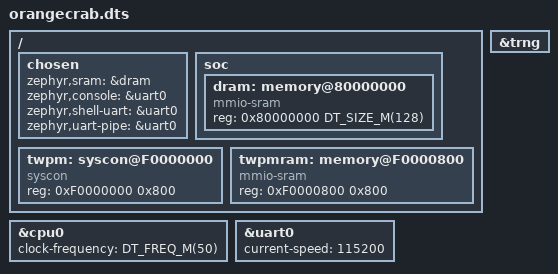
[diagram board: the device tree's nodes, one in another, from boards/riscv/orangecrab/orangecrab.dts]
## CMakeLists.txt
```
cmake_minimum_required(VERSION 3.20.0)

# Required so that Zephyr finds our custom boards. This does not disable lookup
# of boards from Zephyr repo.
set(BOARD_ROOT ${CMAKE_CURRENT_SOURCE_DIR})
find_package(Zephyr REQUIRED HINTS $ENV{ZEPHYR_BASE})

project(app LANGUAGES C VERSION 0.1.0)
zephyr_compile_options(-I${CMAKE_CURRENT_SOURCE_DIR}/../wolf)

target_sources(app PRIVATE
    src/main.c
    src/selftest.c
    src/debug.c
    src/tpm/plat/cancel.c
    src/tpm/plat/clock.c
    src/tpm/plat/entropy.c
    src/tpm/plat/locality.c
    src/tpm/plat/nv.c
    src/tpm/plat/physical_presence.c
    src/tpm/plat/power.c
    src/tpm/plat/run_command.c
    src/tpm/plat/unique.c
    src/tpm/init.c
    src/rng.c
)
target_include_directories(app PRIVATE include)
target_link_libraries(app PRIVATE ms-tpm-20-ref)
target_compile_definitions(app PRIVATE WOLFSSL_USER_SETTINGS)
```

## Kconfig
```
mainmenu "TwPM firmware configuration"

config TWPM_USE_UNSAFE_RNG
	bool "Usafe unsafe RNG"
	help
	  DANGER! Disables use of cryptographically-secure Random Number
	  Generator. This should be used only for testing purposes.

config TWPM_USE_HWINFO
	bool "Use hwinfo to generate TPM unique"
	default y
	depends on HWINFO

config TWPM_NV_EMULATE
	bool "Emulate NV using volatile memory"
	default n
	help
	  When enabled TPM has no persistent memory and all changes will be lost
	  after reset. Used mainly for testing and early platform bringup.

config TWPM_EMULATED_NV_SIZE
	int "Size of emulated NV in bytes"
	default 16384
	depends on TWPM_NV_EMULATE

config TWPM_RNG_TEST
	bool "Enable RNG (Random Number Generator) test"
	default false

source "Kconfig.zephyr"
```

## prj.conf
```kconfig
CONFIG_NEWLIB_LIBC=y
CONFIG_WOLFSSL=y
CONFIG_WOLFSSL_BUILTIN=y
CONFIG_WOLFSSL_SETTINGS_FILE="wolfssl-settings.h"
CONFIG_APP_LINK_WITH_WOLFSSL=y
CONFIG_TPM2_MS_REF=y
CONFIG_ENTROPY_GENERATOR=y
CONFIG_ENTROPY_DEVICE_RANDOM_GENERATOR=y
CONFIG_POSIX_API=y
CONFIG_POSIX_CLOCK=y
CONFIG_PTHREAD_IPC=y
# Increase stack size to avoid stack overflow
# TODO: TPM will run a separate thread because it can't block SPI/LPC, then this
# setting should be revisited
CONFIG_MAIN_STACK_SIZE=4096
CONFIG_HEAP_MEM_POOL_SIZE=32768
CONFIG_FLASH=y
CONFIG_FLASH_MAP=y

# Debugging
CONFIG_LOG=y
CONFIG_DEBUG_INFO=y
CONFIG_EXCEPTION_STACK_TRACE=y
CONFIG_DEBUG_THREAD_INFO=y
CONFIG_INIT_STACKS=y
CONFIG_THREAD_STACK_INFO=y
```

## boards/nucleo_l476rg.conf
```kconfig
CONFIG_GPIO=y
CONFIG_SPI=y
CONFIG_SPI_SLAVE=y
CONFIG_SPI_STM32_DMA=y
CONFIG_SPI_STM32_INTERRUPT=y
CONFIG_SPI_STM32_USE_HW_SS=y
CONFIG_SOC_FLASH_STM32=y
CONFIG_ENTROPY_STM32_RNG=y
CONFIG_HWINFO=y
```

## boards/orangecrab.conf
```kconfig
CONFIG_TWPM_NV_EMULATE=y
CONFIG_TWPM_CONST_UNIQUE=y
```

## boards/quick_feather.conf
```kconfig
# These options make TwPM implementation insecure! Should be removed after we
# gain support for hardware entropy source.
CONFIG_TEST_RANDOM_GENERATOR=y
CONFIG_TIMER_RANDOM_GENERATOR=y
CONFIG_TWPM_USE_UNSAFE_RNG=y
```

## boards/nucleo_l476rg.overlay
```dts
&flash {
	status = "okay";

	partitions {
		compatible = "fixed-partitions";
		#address-cells = <1>;
		#size-cells = <1>;

		nv_integrity: partition@70800 {
			label = "nv_integrity";
			reg = <0x70800 0x800>;
		};

		// NV size must match with NV_MEMORY_SIZE macro in ms-tpm's
		// Implementation.h
		nv_storage: partition@71800 {
			label = "nv_storage";
			reg = <0x71800 0x4000>;
		};
	};
};

&dma1 {
	status = "okay";
};

&spi1 {
	status = "disabled";
};

&spi2 {
	/*
	 * See https://docs.zephyrproject.org/3.0.0/reference/devicetree/bindings/dma/st%2Cstm32-dma-v2.html
	 */
	dmas = <&dma1 5 1 0x20440>,
	       <&dma1 4 1 0x20480>;
	dma-names = "tx", "rx";
};

&spi3 {
	status = "disabled";
};
```

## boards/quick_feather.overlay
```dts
/ {
	aliases {
		lpcfpga = &twpm_lpc_fpga;
	};

	twpm_lpc_fpga: twpm_lpc_fpga@40020000 {
		compatible = "twpm,lpc_fpga";
		reg = <0x40020000 0x400>;
		interrupt-parent = <&nvic>;
		interrupts = <4 1>;
	};
};

&spiflash {
	partitions {
		compatible = "fixed-partitions";
		#address-cells = <1>;
		#size-cells = <1>;

		/* Put directly after the application region.
		 * Based on memory map from
		 * https://github.com/QuickLogic-Corp/qorc-sdk/blob/d61d064146c0ee927aa12b088b3bbbce60615f4d/docs/source/qorc-setup/qorc-flash-memory-map-addresses.svg
		 */

		nv_integrity: partition@ee000 {
			label = "nv_integrity";
			reg = <0xee000 0x1000>;
		};

		// NV size must match with NV_MEMORY_SIZE macro in ms-tpm's
		// Implementation.h
		nv_storage: partition@ef000 {
			label = "nv_storage";
			reg = <0xef000 0x4000>;
		};
	};
};
```

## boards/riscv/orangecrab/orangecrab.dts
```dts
/dts-v1/;

#include <neorv32.dtsi>
#include <freq.h>
#include <mem.h>

/ {
	chosen {
		zephyr,sram = &dram;
		zephyr,console = &uart0;
		zephyr,shell-uart = &uart0;
		zephyr,uart-pipe = &uart0;
	};

	soc {
		dram: memory@80000000 {
			compatible = "mmio-sram";
			reg = <0x80000000 DT_SIZE_M(128)>;
		};
	};

	twpm: syscon@F0000000 {
		compatible = "syscon";
		status = "okay";
		reg = <0xF0000000 0x800>;
	};

	twpmram: memory@F0000800 {
		compatible = "mmio-sram";
		reg = < 0xF0000800 0x800 >;
	};
};

&cpu0 {
	clock-frequency = <DT_FREQ_M(50)>;
};

&uart0 {
	current-speed = <115200>;
	status = "okay";
};

&trng {
	status = "okay";
};
```

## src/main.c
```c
/*
 * Copyright (c) 2022 3mdeb
 *
 * SPDX-License-Identifier: Apache-2.0
 */

#include <zephyr/kernel.h>
#include <zephyr/drivers/gpio.h>
#include <zephyr/drivers/spi.h>
#include <zephyr/drivers/syscon.h>
#include <zephyr/logging/log.h>

#include <twpm/tpm.h>
#include <twpm/test.h>
#include <twpm/platform.h>

#include <string.h>
#include <limits.h>

#include <assert.h>

LOG_MODULE_REGISTER(main);

K_THREAD_STACK_DEFINE(tpm_thread_stack, 16384);
struct k_thread tpm_thread;
k_tid_t tpm_thread_id;
K_SEM_DEFINE(tpm_cmd_sem, 0, 1);

#ifdef CONFIG_TWPM_RNG_TEST
K_THREAD_STACK_DEFINE(rng_thread_stack, 512);
struct k_thread rng_thread;
#endif

static uint8_t tpm_cmd[2048];
static uint32_t tpm_cmd_size = 0;

extern unsigned char _g_locality;

#define TWPM_RAM_BASE       ((void *)DT_REG_ADDR(DT_NODELABEL(twpmram)))

static void tpm_thread_entry(void *p0, void *p1, void *p2) {
	while(1) {
		if (k_sem_take(&tpm_cmd_sem, K_MSEC(1000)) == 0) {
			uint8_t tpm_rsp_buf[2048];
			uint8_t *tpm_response = tpm_rsp_buf;
			uint32_t tpm_response_size = sizeof tpm_rsp_buf;
			const struct device *const dev = DEVICE_DT_GET(DT_NODELABEL(twpm));

			LOG_HEXDUMP_DBG(tpm_cmd, tpm_cmd_size, "TPM command:");
			LOG_INF("Executing %s", tpmdbg_decode_cc(&tpm_cmd[6]));
			twpm_run_command(tpm_cmd_size, tpm_cmd, &tpm_response_size, &tpm_response);

			if (tpm_response_size > 2048) {
				LOG_ERR("Illegal response size %x", tpm_response_size);
				k_oops();
			}

			LOG_HEXDUMP_DBG(tpm_response, tpm_response_size, "TPM response:");
			LOG_INF("TPM command result: %s", tpmdbg_decode_rc(&tpm_response[6]));

			memcpy(TWPM_RAM_BASE, tpm_response, tpm_response_size);
			syscon_write_reg(dev, TWPM_REG_COMPLETE, 1);

			irq_enable(TWPM_IRQ);
		} else {
			// Update internal state of 64-bit emulated clock (STM32
			// provides only 32-bit clock). We need to do this
			// periodically to detect clock overflows.
			_plat__TimerRead();
		}
	}
}

static void twpm_isr(const struct device *const dev)
{
	uint32_t op_type = 0;
	uint32_t locality = 0;

	irq_disable(TWPM_IRQ);

	syscon_read_reg(dev, TWPM_REG_OP_TYPE, &op_type);
	syscon_read_reg(dev, TWPM_REG_BUF_SIZE, &tpm_cmd_size);
	syscon_read_reg(dev, TWPM_REG_LOCALITY, &locality);

	LOG_INF("IRQ: op_type = %x, cmd_size = %x, locality = %x",
	        op_type, tpm_cmd_size, locality);

	if (op_type == TWPM_REG_OP_TYPE_CMD) {
		if (tpm_cmd_size > 2048) {
			LOG_ERR("Illegal command size %x", tpm_cmd_size);
			k_oops();
		}
		if (locality > 4) {
			LOG_ERR("Illegal locality %x", locality);
			k_oops();
		}
		_g_locality = locality & 0x0F;

		memcpy(tpm_cmd, TWPM_RAM_BASE, tpm_cmd_size);
		k_sem_give(&tpm_cmd_sem);
	} else {
		LOG_ERR("Unknown operation requested, giving up");
		k_oops();
	}
}

#ifdef CONFIG_TWPM_RNG_TEST
extern void twpm_test_rng();
#endif

int main(void)
{
	LOG_INF("Starting TwPM");

	IRQ_CONNECT(TWPM_IRQ, 0, twpm_isr, DEVICE_DT_GET(DT_NODELABEL(twpm)), 0);
	irq_enable(TWPM_IRQ);

	twpm_init();
	//twpm_selftest();

	tpm_thread_id = k_thread_create(&tpm_thread, tpm_thread_stack,
					K_THREAD_STACK_SIZEOF(tpm_thread_stack),
					tpm_thread_entry, NULL, NULL, NULL, 5, 0,
					K_NO_WAIT);

#ifdef CONFIG_TWPM_RNG_TEST
	k_thread_create(&rng_thread, rng_thread_stack,
			K_THREAD_STACK_SIZEOF(rng_thread_stack), twpm_test_rng,
			NULL, NULL, NULL, 5, 0, K_NO_WAIT);
#endif

	return 0;
}
```

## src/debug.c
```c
// Based on ms-tpm-20-ref/Samples/Nucleo-TPM/Shared/TPMDevice/src/TpmDevice.c

#include <twpm/test.h>
#include <stdio.h>

#include <Implementation.h>
#include <GpMacros.h>
#include <Capabilities.h>
#include <Memory_fp.h>
#include <TpmTypes.h>

#define TPM_RC_MAX_FM1 (TPM_RC)(RC_FMT1 + 0x03F)

typedef struct
{
    uint32_t index;
    char* str;
} lookup_t;

const lookup_t tpm_cc_table[] =
{
#if CC_NV_UndefineSpaceSpecial == YES
    {TPM_CC_NV_UndefineSpaceSpecial, "TPM_CC_NV_UndefineSpaceSpecial"},
#endif
#if CC_EvictControl == YES
    {TPM_CC_EvictControl, "TPM_CC_EvictControl"},
#endif
#if CC_HierarchyControl == YES
    {TPM_CC_HierarchyControl, "TPM_CC_HierarchyControl"},
#endif
#if CC_NV_UndefineSpace == YES
    {TPM_CC_NV_UndefineSpace, "TPM_CC_NV_UndefineSpace"},
#endif
#if CC_ChangeEPS == YES
    {TPM_CC_ChangeEPS, "TPM_CC_ChangeEPS"},
#endif
#if CC_ChangePPS == YES
    {TPM_CC_ChangePPS, "TPM_CC_ChangePPS"},
#endif
#if CC_Clear == YES
    {TPM_CC_Clear, "TPM_CC_Clear"},
#endif
#if CC_ClearControl == YES
    {TPM_CC_ClearControl, "TPM_CC_ClearControl"},
#endif
#if CC_ClockSet == YES
    {TPM_CC_ClockSet, "TPM_CC_ClockSet"},
#endif
#if CC_HierarchyChangeAuth == YES
    {TPM_CC_HierarchyChangeAuth, "TPM_CC_HierarchyChangeAuth"},
#endif
#if CC_NV_DefineSpace == YES
    {TPM_CC_NV_DefineSpace, "TPM_CC_NV_DefineSpace"},
#endif
#if CC_PCR_Allocate == YES
    {TPM_CC_PCR_Allocate, "TPM_CC_PCR_Allocate"},
#endif
#if CC_PCR_SetAuthPolicy == YES
    {TPM_CC_PCR_SetAuthPolicy, "TPM_CC_PCR_SetAuthPolicy"},
#endif
#if CC_PP_Commands == YES
    {TPM_CC_PP_Commands, "TPM_CC_PP_Commands"},
#endif
#if CC_SetPrimaryPolicy == YES
    {TPM_CC_SetPrimaryPolicy, "TPM_CC_SetPrimaryPolicy"},
#endif
#if CC_FieldUpgradeStart == YES
    {TPM_CC_FieldUpgradeStart, "TPM_CC_FieldUpgradeStart"},
#endif
#if CC_ClockRateAdjust == YES
    {TPM_CC_ClockRateAdjust, "TPM_CC_ClockRateAdjust"},
#endif
#if CC_CreatePrimary == YES
    {TPM_CC_CreatePrimary, "TPM_CC_CreatePrimary"},
#endif
#if CC_NV_GlobalWriteLock == YES
    {TPM_CC_NV_GlobalWriteLock, "TPM_CC_NV_GlobalWriteLock"},
#endif
#if CC_GetCommandAuditDigest == YES
    {TPM_CC_GetCommandAuditDigest, "TPM_CC_GetCommandAuditDigest"},
#endif
#if CC_NV_Increment == YES
    {TPM_CC_NV_Increment, "TPM_CC_NV_Increment"},
#endif
#if CC_NV_SetBits == YES
    {TPM_CC_NV_SetBits, "TPM_CC_NV_SetBits"},
#endif
#if CC_NV_Extend == YES
    {TPM_CC_NV_Extend, "TPM_CC_NV_Extend"},
#endif
#if CC_NV_Write == YES
    {TPM_CC_NV_Write, "TPM_CC_NV_Write"},
#endif
#if CC_NV_WriteLock == YES
    {TPM_CC_NV_WriteLock, "TPM_CC_NV_WriteLock"},
#endif
#if CC_DictionaryAttackLockReset == YES
    {TPM_CC_DictionaryAttackLockReset, "TPM_CC_DictionaryAttackLockReset"},
#endif
#if CC_DictionaryAttackParameters == YES
    {TPM_CC_DictionaryAttackParameters, "TPM_CC_DictionaryAttackParameters"},
#endif
#if CC_NV_ChangeAuth == YES
    {TPM_CC_NV_ChangeAuth, "TPM_CC_NV_ChangeAuth"},
#endif
#if CC_PCR_Event == YES
    {TPM_CC_PCR_Event, "TPM_CC_PCR_Event"},
#endif
#if CC_PCR_Reset == YES
    {TPM_CC_PCR_Reset, "TPM_CC_PCR_Reset"},
#endif
#if CC_SequenceComplete == YES
    {TPM_CC_SequenceComplete, "TPM_CC_SequenceComplete"},
#endif
#if CC_SetAlgorithmSet == YES
    {TPM_CC_SetAlgorithmSet, "TPM_CC_SetAlgorithmSet"},
#endif
#if CC_SetCommandCodeAuditStatus == YES
    {TPM_CC_SetCommandCodeAuditStatus, "TPM_CC_SetCommandCodeAuditStatus"},
#endif
#if CC_FieldUpgradeData == YES
    {TPM_CC_FieldUpgradeData, "TPM_CC_FieldUpgradeData"},
#endif
#if CC_IncrementalSelfTest == YES
    {TPM_CC_IncrementalSelfTest, "TPM_CC_IncrementalSelfTest"},
#endif
#if CC_SelfTest == YES
    {TPM_CC_SelfTest, "TPM_CC_SelfTest"},
#endif
#if CC_Startup == YES
    {TPM_CC_Startup, "TPM_CC_Startup"},
#endif
#if CC_Shutdown == YES
    {TPM_CC_Shutdown, "TPM_CC_Shutdown"},
#endif
#if CC_StirRandom == YES
    {TPM_CC_StirRandom, "TPM_CC_StirRandom"},
#endif
#if CC_ActivateCredential == YES
    {TPM_CC_ActivateCredential, "TPM_CC_ActivateCredential"},
#endif
#if CC_Certify == YES
    {TPM_CC_Certify, "TPM_CC_Certify"},
#endif
#if CC_PolicyNV == YES
    {TPM_CC_PolicyNV, "TPM_CC_PolicyNV"},
#endif
#if CC_CertifyCreation == YES
    {TPM_CC_CertifyCreation, "TPM_CC_CertifyCreation"},
#endif
#if CC_Duplicate == YES
    {TPM_CC_Duplicate, "TPM_CC_Duplicate"},
#endif
#if CC_GetTime == YES
    {TPM_CC_GetTime, "TPM_CC_GetTime"},
#endif
#if CC_GetSessionAuditDigest == YES
    {TPM_CC_GetSessionAuditDigest, "TPM_CC_GetSessionAuditDigest"},
#endif
#if CC_NV_Read == YES
    {TPM_CC_NV_Read, "TPM_CC_NV_Read"},
#endif
#if CC_NV_ReadLock == YES
    {TPM_CC_NV_ReadLock, "TPM_CC_NV_ReadLock"},
#endif
#if CC_ObjectChangeAuth == YES
    {TPM_CC_ObjectChangeAuth, "TPM_CC_ObjectChangeAuth"},
#endif
#if CC_PolicySecret == YES
    {TPM_CC_PolicySecret, "TPM_CC_PolicySecret"},
#endif
#if CC_Rewrap == YES
    {TPM_CC_Rewrap, "TPM_CC_Rewrap"},
#endif
#if CC_Create == YES
    {TPM_CC_Create, "TPM_CC_Create"},
#endif
#if CC_ECDH_ZGen == YES
    {TPM_CC_ECDH_ZGen, "TPM_CC_ECDH_ZGen"},
#endif
#if CC_HMAC == YES
    {TPM_CC_HMAC, "TPM_CC_HMAC"},
#endif
#if CC_MAC == YES
    {TPM_CC_MAC, "TPM_CC_MAC"},
#endif
#if CC_Import == YES
    {TPM_CC_Import, "TPM_CC_Import"},
#endif
#if CC_Load == YES
    {TPM_CC_Load, "TPM_CC_Load"},
#endif
#if CC_Quote == YES
    {TPM_CC_Quote, "TPM_CC_Quote"},
#endif
#if CC_RSA_Decrypt == YES
    {TPM_CC_RSA_Decrypt, "TPM_CC_RSA_Decrypt"},
#endif
#if CC_HMAC_Start == YES
    {TPM_CC_HMAC_Start, "TPM_CC_HMAC_Start"},
#endif
#if CC_MAC_Start == YES
    {TPM_CC_MAC_Start, "TPM_CC_MAC_Start"},
#endif
#if CC_SequenceUpdate == YES
    {TPM_CC_SequenceUpdate, "TPM_CC_SequenceUpdate"},
#endif
#if CC_Sign == YES
    {TPM_CC_Sign, "TPM_CC_Sign"},
#endif
#if CC_Unseal == YES
    {TPM_CC_Unseal, "TPM_CC_Unseal"},
#endif
#if CC_PolicySigned == YES
    {TPM_CC_PolicySigned, "TPM_CC_PolicySigned"},
#endif
#if CC_ContextLoad == YES
    {TPM_CC_ContextLoad, "TPM_CC_ContextLoad"},
#endif
#if CC_ContextSave == YES
    {TPM_CC_ContextSave, "TPM_CC_ContextSave"},
#endif
#if CC_ECDH_KeyGen == YES
    {TPM_CC_ECDH_KeyGen, "TPM_CC_ECDH_KeyGen"},
#endif
#if CC_EncryptDecrypt == YES
    {TPM_CC_EncryptDecrypt, "TPM_CC_EncryptDecrypt"},
#endif
#if CC_FlushContext == YES
    {TPM_CC_FlushContext, "TPM_CC_FlushContext"},
#endif
#if CC_LoadExternal == YES
    {TPM_CC_LoadExternal, "TPM_CC_LoadExternal"},
#endif
#if CC_MakeCredential == YES
    {TPM_CC_MakeCredential, "TPM_CC_MakeCredential"},
#endif
#if CC_NV_ReadPublic == YES
    {TPM_CC_NV_ReadPublic, "TPM_CC_NV_ReadPublic"},
#endif
#if CC_PolicyAuthorize == YES
    {TPM_CC_PolicyAuthorize, "TPM_CC_PolicyAuthorize"},
#endif
#if CC_PolicyAuthValue == YES
    {TPM_CC_PolicyAuthValue, "TPM_CC_PolicyAuthValue"},
#endif
#if CC_PolicyCommandCode == YES
    {TPM_CC_PolicyCommandCode, "TPM_CC_PolicyCommandCode"},
#endif
#if CC_PolicyCounterTimer == YES
    {TPM_CC_PolicyCounterTimer, "TPM_CC_PolicyCounterTimer"},
#endif
#if CC_PolicyCpHash == YES
    {TPM_CC_PolicyCpHash, "TPM_CC_PolicyCpHash"},
#endif
#if CC_PolicyLocality == YES
    {TPM_CC_PolicyLocality, "TPM_CC_PolicyLocality"},
#endif
#if CC_PolicyNameHash == YES
    {TPM_CC_PolicyNameHash, "TPM_CC_PolicyNameHash"},
#endif
#if CC_PolicyOR == YES
    {TPM_CC_PolicyOR, "TPM_CC_PolicyOR"},
#endif
#if CC_PolicyTicket == YES
    {TPM_CC_PolicyTicket, "TPM_CC_PolicyTicket"},
#endif
#if CC_ReadPublic == YES
    {TPM_CC_ReadPublic, "TPM_CC_ReadPublic"},
#endif
#if CC_RSA_Encrypt == YES
    {TPM_CC_RSA_Encrypt, "TPM_CC_RSA_Encrypt"},
#endif
#if CC_StartAuthSession == YES
    {TPM_CC_StartAuthSession, "TPM_CC_StartAuthSession"},
#endif
#if CC_VerifySignature == YES
    {TPM_CC_VerifySignature, "TPM_CC_VerifySignature"},
#endif
#if CC_ECC_Parameters == YES
    {TPM_CC_ECC_Parameters, "TPM_CC_ECC_Parameters"},
#endif
#if CC_FirmwareRead == YES
    {TPM_CC_FirmwareRead, "TPM_CC_FirmwareRead"},
#endif
#if CC_GetCapability == YES
    {TPM_CC_GetCapability, "TPM_CC_GetCapability"},
#endif
#if CC_GetRandom == YES
    {TPM_CC_GetRandom, "TPM_CC_GetRandom"},
#endif
#if CC_GetTestResult == YES
    {TPM_CC_GetTestResult, "TPM_CC_GetTestResult"},
#endif
#if CC_Hash == YES
    {TPM_CC_Hash, "TPM_CC_Hash"},
#endif
#if CC_PCR_Read == YES
    {TPM_CC_PCR_Read, "TPM_CC_PCR_Read"},
#endif
#if CC_PolicyPCR == YES
    {TPM_CC_PolicyPCR, "TPM_CC_PolicyPCR"},
#endif
#if CC_PolicyRestart == YES
    {TPM_CC_PolicyRestart, "TPM_CC_PolicyRestart"},
#endif
#if CC_ReadClock == YES
    {TPM_CC_ReadClock, "TPM_CC_ReadClock"},
#endif
#if CC_PCR_Extend == YES
    {TPM_CC_PCR_Extend, "TPM_CC_PCR_Extend"},
#endif
#if CC_PCR_SetAuthValue == YES
    {TPM_CC_PCR_SetAuthValue, "TPM_CC_PCR_SetAuthValue"},
#endif
#if CC_NV_Certify == YES
    {TPM_CC_NV_Certify, "TPM_CC_NV_Certify"},
#endif
#if CC_EventSequenceComplete == YES
    {TPM_CC_EventSequenceComplete, "TPM_CC_EventSequenceComplete"},
#endif
#if CC_HashSequenceStart == YES
    {TPM_CC_HashSequenceStart, "TPM_CC_HashSequenceStart"},
#endif
#if CC_PolicyPhysicalPresence == YES
    {TPM_CC_PolicyPhysicalPresence, "TPM_CC_PolicyPhysicalPresence"},
#endif
#if CC_PolicyDuplicationSelect == YES
    {TPM_CC_PolicyDuplicationSelect, "TPM_CC_PolicyDuplicationSelect"},
#endif
#if CC_PolicyGetDigest == YES
    {TPM_CC_PolicyGetDigest, "TPM_CC_PolicyGetDigest"},
#endif
#if CC_TestParms == YES
    {TPM_CC_TestParms, "TPM_CC_TestParms"},
#endif
#if CC_Commit == YES
    {TPM_CC_Commit, "TPM_CC_Commit"},
#endif
#if CC_PolicyPassword == YES
    {TPM_CC_PolicyPassword, "TPM_CC_PolicyPassword"},
#endif
#if CC_ZGen_2Phase == YES
    {TPM_CC_ZGen_2Phase, "TPM_CC_ZGen_2Phase"},
#endif
#if CC_EC_Ephemeral == YES
    {TPM_CC_EC_Ephemeral, "TPM_CC_EC_Ephemeral"},
#endif
#if CC_PolicyNvWritten == YES
    {TPM_CC_PolicyNvWritten, "TPM_CC_PolicyNvWritten"},
#endif
#if CC_PolicyTemplate == YES
    {TPM_CC_PolicyTemplate, "TPM_CC_PolicyTemplate"},
#endif
#if CC_CreateLoaded == YES
    {TPM_CC_CreateLoaded, "TPM_CC_CreateLoaded"},
#endif
#if CC_PolicyAuthorizeNV == YES
    {TPM_CC_PolicyAuthorizeNV, "TPM_CC_PolicyAuthorizeNV"},
#endif
#if CC_EncryptDecrypt2 == YES
    {TPM_CC_EncryptDecrypt2, "TPM_CC_EncryptDecrypt2"},
#endif
#if CC_AC_GetCapability == YES
    {TPM_CC_AC_GetCapability, "TPM_CC_AC_GetCapability"},
#endif
#if CC_AC_Send == YES
    {TPM_CC_AC_Send, "TPM_CC_AC_Send"},
#endif
#if CC_Policy_AC_SendSelect == YES
    {TPM_CC_Policy_AC_SendSelect, "TPM_CC_Policy_AC_SendSelect"},
#endif
    {(uint32_t)-1, NULL}
};

const lookup_t tpm_rc_globalCodes[] = {
    {TPM_RC_SUCCESS, "TPM_RC_SUCCESS"},
    {TPM_RC_BAD_TAG, "TPM_RC_BAD_TAG"},
    {(uint32_t)-1, NULL}
};

const lookup_t tpm_rc_formatZeroCodes[] = {
    {TPM_RC_INITIALIZE, "TPM_RC_INITIALIZE"},
    {TPM_RC_FAILURE, "TPM_RC_FAILURE"},
    {TPM_RC_SEQUENCE, "TPM_RC_SEQUENCE"},
    {TPM_RC_PRIVATE, "TPM_RC_PRIVATE"},
    {TPM_RC_HMAC, "TPM_RC_HMAC"},
    {TPM_RC_DISABLED, "TPM_RC_DISABLED"},
    {TPM_RC_EXCLUSIVE, "TPM_RC_EXCLUSIVE"},
    {TPM_RC_AUTH_TYPE, "TPM_RC_AUTH_TYPE"},
    {TPM_RC_AUTH_MISSING, "TPM_RC_AUTH_MISSING"},
    {TPM_RC_POLICY, "TPM_RC_POLICY"},
    {TPM_RC_PCR, "TPM_RC_PCR"},
    {TPM_RC_PCR_CHANGED, "TPM_RC_PCR_CHANGED"},
    {TPM_RC_UPGRADE, "TPM_RC_UPGRADE"},
    {TPM_RC_TOO_MANY_CONTEXTS, "TPM_RC_TOO_MANY_CONTEXTS"},
    {TPM_RC_AUTH_UNAVAILABLE, "TPM_RC_AUTH_UNAVAILABLE"},
    {TPM_RC_REBOOT, "TPM_RC_REBOOT"},
    {TPM_RC_UNBALANCED, "TPM_RC_UNBALANCED"},
    {TPM_RC_COMMAND_SIZE, "TPM_RC_COMMAND_SIZE"},
    {TPM_RC_COMMAND_CODE, "TPM_RC_COMMAND_CODE"},
    {TPM_RC_AUTHSIZE, "TPM_RC_AUTHSIZE"},
    {TPM_RC_AUTH_CONTEXT, "TPM_RC_AUTH_CONTEXT"},
    {TPM_RC_NV_RANGE, "TPM_RC_NV_RANGE"},
    {TPM_RC_NV_SIZE, "TPM_RC_NV_SIZE"},
    {TPM_RC_NV_LOCKED, "TPM_RC_NV_LOCKED"},
    {TPM_RC_NV_AUTHORIZATION, "TPM_RC_NV_AUTHORIZATION"},
    {TPM_RC_NV_UNINITIALIZED, "TPM_RC_NV_UNINITIALIZED"},
    {TPM_RC_NV_SPACE, "TPM_RC_NV_SPACE"},
    {TPM_RC_NV_DEFINED, "TPM_RC_NV_DEFINED"},
    {TPM_RC_BAD_CONTEXT, "TPM_RC_BAD_CONTEXT"},
    {TPM_RC_CPHASH, "TPM_RC_CPHASH"},
    {TPM_RC_PARENT, "TPM_RC_PARENT"},
    {TPM_RC_NEEDS_TEST, "TPM_RC_NEEDS_TEST"},
    {TPM_RC_NO_RESULT, "TPM_RC_NO_RESULT"},
    {TPM_RC_SENSITIVE, "TPM_RC_SENSITIVE"},
    {(uint32_t)-1, NULL}
};

const lookup_t tpm_rc_warningCodes[] = {
    {TPM_RC_CONTEXT_GAP, "TPM_RC_CONTEXT_GAP"},
    {TPM_RC_OBJECT_MEMORY, "TPM_RC_OBJECT_MEMORY"},
    {TPM_RC_SESSION_MEMORY, "TPM_RC_SESSION_MEMORY"},
    {TPM_RC_MEMORY, "TPM_RC_MEMORY"},
    {TPM_RC_SESSION_HANDLES, "TPM_RC_SESSION_HANDLES"},
    {TPM_RC_OBJECT_HANDLES, "TPM_RC_OBJECT_HANDLES"},
    {TPM_RC_LOCALITY, "TPM_RC_LOCALITY"},
    {TPM_RC_YIELDED, "TPM_RC_YIELDED"},
    {TPM_RC_CANCELED, "TPM_RC_CANCELED"},
    {TPM_RC_TESTING, "TPM_RC_TESTING"},
    {TPM_RC_REFERENCE_H0, "TPM_RC_REFERENCE_H0"},
    {TPM_RC_REFERENCE_H1, "TPM_RC_REFERENCE_H1"},
    {TPM_RC_REFERENCE_H2, "TPM_RC_REFERENCE_H2"},
    {TPM_RC_REFERENCE_H3, "TPM_RC_REFERENCE_H3"},
    {TPM_RC_REFERENCE_H4, "TPM_RC_REFERENCE_H4"},
    {TPM_RC_REFERENCE_H5, "TPM_RC_REFERENCE_H5"},
    {TPM_RC_REFERENCE_H6, "TPM_RC_REFERENCE_H6"},
    {TPM_RC_REFERENCE_S0, "TPM_RC_REFERENCE_S0"},
    {TPM_RC_REFERENCE_S1, "TPM_RC_REFERENCE_S1"},
    {TPM_RC_REFERENCE_S2, "TPM_RC_REFERENCE_S2"},
    {TPM_RC_REFERENCE_S3, "TPM_RC_REFERENCE_S3"},
    {TPM_RC_REFERENCE_S4, "TPM_RC_REFERENCE_S4"},
    {TPM_RC_REFERENCE_S5, "TPM_RC_REFERENCE_S5"},
    {TPM_RC_REFERENCE_S6, "TPM_RC_REFERENCE_S6"},
    {TPM_RC_NV_RATE, "TPM_RC_NV_RATE"},
    {TPM_RC_LOCKOUT, "TPM_RC_LOCKOUT"},
    {TPM_RC_RETRY, "TPM_RC_RETRY"},
    {TPM_RC_NV_UNAVAILABLE, "TPM_RC_NV_UNAVAILABLE"},
    {(uint32_t)-1, NULL}
};

const lookup_t tpm_rc_formatCodes[] = {
    {TPM_RCS_ASYMMETRIC, "TPM_RCS_ASYMMETRIC"},
    {TPM_RC_ATTRIBUTES, "TPM_RC_ATTRIBUTES"},
    {TPM_RCS_ATTRIBUTES, "TPM_RCS_ATTRIBUTES"},
    {TPM_RC_HASH, "TPM_RC_HASH"},
    {TPM_RCS_HASH, "TPM_RCS_HASH"},
    {TPM_RC_VALUE, "TPM_RC_VALUE"},
    {TPM_RCS_VALUE, "TPM_RCS_VALUE"},
    {TPM_RC_HIERARCHY, "TPM_RC_HIERARCHY"},
    {TPM_RCS_HIERARCHY, "TPM_RCS_HIERARCHY"},
    {TPM_RC_KEY_SIZE, "TPM_RC_KEY_SIZE"},
    {TPM_RCS_KEY_SIZE, "TPM_RCS_KEY_SIZE"},
    {TPM_RC_MGF, "TPM_RC_MGF"},
    {TPM_RCS_MGF, "TPM_RCS_MGF"},
    {TPM_RC_MODE, "TPM_RC_MODE"},
    {TPM_RCS_MODE, "TPM_RCS_MODE"},
    {TPM_RC_TYPE, "TPM_RC_TYPE"},
    {TPM_RCS_TYPE, "TPM_RCS_TYPE"},
    {TPM_RC_HANDLE, "TPM_RC_HANDLE"},
    {TPM_RCS_HANDLE, "TPM_RCS_HANDLE"},
    {TPM_RC_KDF, "TPM_RC_KDF"},
    {TPM_RCS_KDF, "TPM_RCS_KDF"},
    {TPM_RC_RANGE, "TPM_RC_RANGE"},
    {TPM_RCS_RANGE, "TPM_RCS_RANGE"},
    {TPM_RC_AUTH_FAIL, "TPM_RC_AUTH_FAIL"},
    {TPM_RCS_AUTH_FAIL, "TPM_RCS_AUTH_FAIL"},
    {TPM_RC_NONCE, "TPM_RC_NONCE"},
    {TPM_RCS_NONCE, "TPM_RCS_NONCE"},
    {TPM_RC_PP, "TPM_RC_PP"},
    {TPM_RCS_PP, "TPM_RCS_PP"},
    {TPM_RC_SCHEME, "TPM_RC_SCHEME"},
    {TPM_RCS_SCHEME, "TPM_RCS_SCHEME"},
    {TPM_RC_SIZE, "TPM_RC_SIZE"},
    {TPM_RCS_SIZE, "TPM_RCS_SIZE"},
    {TPM_RC_SYMMETRIC, "TPM_RC_SYMMETRIC"},
    {TPM_RCS_SYMMETRIC, "TPM_RCS_SYMMETRIC"},
    {TPM_RC_TAG, "TPM_RC_TAG"},
    {TPM_RCS_TAG, "TPM_RCS_TAG"},
    {TPM_RC_SELECTOR, "TPM_RC_SELECTOR"},
    {TPM_RCS_SELECTOR, "TPM_RCS_SELECTOR"},
    {TPM_RC_INSUFFICIENT, "TPM_RC_INSUFFICIENT"},
    {TPM_RCS_INSUFFICIENT, "TPM_RCS_INSUFFICIENT"},
    {TPM_RC_SIGNATURE, "TPM_RC_SIGNATURE"},
    {TPM_RCS_SIGNATURE, "TPM_RCS_SIGNATURE"},
    {TPM_RC_KEY, "TPM_RC_KEY"},
    {TPM_RCS_KEY, "TPM_RCS_KEY"},
    {TPM_RC_POLICY_FAIL, "TPM_RC_POLICY_FAIL"},
    {TPM_RCS_POLICY_FAIL, "TPM_RCS_POLICY_FAIL"},
    {TPM_RC_INTEGRITY, "TPM_RC_INTEGRITY"},
    {TPM_RCS_INTEGRITY, "TPM_RCS_INTEGRITY"},
    {TPM_RC_TICKET, "TPM_RC_TICKET"},
    {TPM_RCS_TICKET, "TPM_RCS_TICKET"},
    {TPM_RC_RESERVED_BITS, "TPM_RC_RESERVED_BITS"},
    {TPM_RCS_RESERVED_BITS, "TPM_RCS_RESERVED_BITS"},
    {TPM_RC_BAD_AUTH, "TPM_RC_BAD_AUTH"},
    {TPM_RCS_BAD_AUTH, "TPM_RCS_BAD_AUTH"},
    {TPM_RC_EXPIRED, "TPM_RC_EXPIRED"},
    {TPM_RCS_EXPIRED, "TPM_RCS_EXPIRED"},
    {TPM_RC_POLICY_CC, "TPM_RC_POLICY_CC"},
    {TPM_RCS_POLICY_CC, "TPM_RCS_POLICY_CC"},
    {TPM_RC_BINDING, "TPM_RC_BINDING"},
    {TPM_RCS_BINDING, "TPM_RCS_BINDING"},
    {TPM_RC_CURVE, "TPM_RC_CURVE"},
    {TPM_RCS_CURVE, "TPM_RCS_CURVE"},
    {TPM_RC_ECC_POINT, "TPM_RC_ECC_POINT"},
    {TPM_RCS_ECC_POINT, "TPM_RCS_ECC_POINT"},
    {(uint32_t)-1, NULL}
};

char decodeBuf[100];

char* tpmdbg_decode_cc(uint8_t* in)
{
    TPM_CC cc = BYTE_ARRAY_TO_UINT32(in);
#ifndef NDEBUG
    uint32_t n;
    for(n = 0; ((tpm_cc_table[n].index != (uint32_t)-1) && (tpm_cc_table[n].index != cc)) ; n++ );
    if(tpm_cc_table[n].index != (uint32_t)-1)
    {
        sprintf(decodeBuf, "%s()", tpm_cc_table[n].str);
    }
    else
    {
#endif
        sprintf(decodeBuf, "0x%03x", (unsigned int)cc);
#ifndef NDEBUG
    }
#endif
    return decodeBuf;
}

char* tpmdbg_decode_rc(uint8_t* in)
{
    TPM_RC rc = BYTE_ARRAY_TO_UINT32(in);

    uint32_t n;
    uint32_t cursor = 0;

    for(n = 0; ((tpm_rc_globalCodes[n].index != (uint32_t)-1) && (tpm_rc_globalCodes[n].index != rc)) ; n++ );
    if(tpm_rc_globalCodes[n].index != (uint32_t)-1)
    {
        cursor = sprintf(decodeBuf, "{%s}", tpm_rc_globalCodes[n].str);
    }
    else if((rc & RC_FMT1) == RC_FMT1)
    {
        if(rc & TPM_RC_P)
        {
            cursor = sprintf(decodeBuf, "{RC_FMT1 | TPM_RC_P | TPM_RC_%X | ", (unsigned int)((rc & 0x00000f00) >> 8));
        }
        else if(rc & TPM_RC_S)
        {
            cursor = sprintf(decodeBuf, "{RC_FMT1 | TPM_RC_S | TPM_RC_%X | ", (unsigned int)((rc & 0x00000700) >> 8));
        }
        else
        {
            cursor = sprintf(decodeBuf, "{RC_FMT1 | TPM_RC_H | TPM_RC_%X | ", (unsigned int)((rc & 0x00000700) >> 8));
        }

        for(n = 0; ((tpm_rc_formatCodes[n].index != (uint32_t)-1) && (tpm_rc_formatCodes[n].index != (rc & TPM_RC_MAX_FM1))) ; n++ );
        if(tpm_rc_formatCodes[n].index != (uint32_t)-1)
        {
            cursor = sprintf(&decodeBuf[cursor], "%s}", tpm_rc_formatCodes[n].str);
        }
        else
        {
            cursor = 0;
        }
    }
    else if((rc & RC_WARN) == RC_WARN)
    {
        for(n = 0; ((tpm_rc_warningCodes[n].index != (uint32_t)-1) && (tpm_rc_warningCodes[n].index != rc)) ; n++ );
        if(tpm_rc_warningCodes[n].index != (uint32_t)-1)
        {
            cursor = sprintf(decodeBuf, "{RC_VER1 | RC_WARN | %s}", tpm_rc_warningCodes[n].str);
        }
    }
    else if((rc & RC_VER1) == RC_VER1)
    {
        for(n = 0; ((tpm_rc_formatZeroCodes[n].index != (uint32_t)-1) && (tpm_rc_formatZeroCodes[n].index != rc)) ; n++ );
        if(tpm_rc_formatZeroCodes[n].index != (uint32_t)-1)
        {
            cursor = sprintf(decodeBuf, "{RC_VER1 | %s}", tpm_rc_formatZeroCodes[n].str);
        }
    }

    if(cursor == 0)
    {
        sprintf(decodeBuf, "0x%03x", (unsigned int)rc);
        return decodeBuf;
    }
    return decodeBuf;
}
```

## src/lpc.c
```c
#include <zephyr/device.h>
#include <zephyr/devicetree.h>
#include <zephyr/irq.h>
#include <zephyr/logging/log.h>

// TOOD: make configurable
LOG_MODULE_REGISTER(LPC, LOG_LEVEL_DBG);

static void irq_handler(void *param) {
	(void)param;

	LOG_INF("IRQ happened");
}

void twpm_lpc_init() {
	struct {
		uint32_t base;
		uint32_t size;
	} info = DT_PROP(DT_ALIAS(lpcfpga), reg);

	uint32_t *reg = (uint32_t *)info.base;

	LOG_INF("Found controller at 0x%08x-0x%08x", info.base, info.base + info.size - 1);
	LOG_INF("reg[0] = 0x%08x", reg[0]);
	LOG_INF("reg[1] = 0x%08x", reg[1]);
	LOG_INF("reg[2] = 0x%08x", reg[2]);
	LOG_INF("reg[3] = 0x%08x", reg[3]);
	LOG_INF("reg[4] = 0x%08x", reg[4]);
	LOG_INF("reg[5] = 0x%08x", reg[5]);

	IRQ_CONNECT(4, 1, irq_handler, NULL, 0);
	irq_enable(4);

	LOG_INF("IRQ enabled");
}
```

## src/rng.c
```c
#include "zephyr/sys/printk.h"
#include <string.h>
#include <zephyr/kernel.h>
#include <zephyr/shell/shell.h>
#include <zephyr/random/random.h>
#include <assert.h>

#ifdef CONFIG_TWPM_RNG_TEST
static uint8_t buffer[64];
char buffer_ascii[sizeof buffer * 2 + 1];

static int rng_test(const struct shell *sh) {
	int ret = sys_csrand_get(buffer, sizeof buffer);
	if (ret == 0) {
		for (int i = 0; i < sizeof buffer; i++) {
			uint8_t t;

			t = buffer[i] >> 4;
			buffer_ascii[i * 2] = t < 10 ? t + '0' : t + 'a' - 10;

			t = buffer[i] & 0x0f;
			buffer_ascii[i * 2 + 1] = t < 10 ? t + '0' : t + 'a' - 10;
		}

		buffer_ascii[sizeof buffer_ascii - 1] = '\0';

		if (sh)
			shell_print(sh, "%s", buffer_ascii);
		else
			printk("%s\n", buffer_ascii);
	} else {
		if (sh)
			shell_error(sh, "RNG error %d", ret);
		else
			printk("RNG error %d\n", ret);
	}

	return ret;
}

void twpm_test_rng() {
	while (true) {
		int ret = rng_test(NULL);
		if (ret < 0) {
			printk("RNG test fail");
			k_panic();
		}

		k_yield();
	}
}

#ifdef CONFIG_SHELL
static const struct shell *shell;
static struct k_work_delayable work;

static void rng_work(struct k_work *_work) {
	ARG_UNUSED(_work);

	assert(shell != NULL);

	int ret = rng_test(shell);

	if (ret < 0) {
		k_work_cancel_delayable(&work);
		shell_set_bypass(shell, NULL);
		shell = NULL;
	} else
		k_work_reschedule(&work, K_NO_WAIT);
}

static void rng_bypass(const struct shell *sh, uint8_t *data, size_t len) {
	assert(shell != NULL);
	assert(shell == sh);

	for (size_t i = 0; i < len; i++) {
		if (data[i] == 0x03) {
			k_work_cancel_delayable(&work);
			shell_set_bypass(shell, NULL);
			shell = NULL;
			break;
		}
	}

}

static int cmd_rng_test(const struct shell *sh, size_t argc, char *argv[])
{
	ARG_UNUSED(argc);
	ARG_UNUSED(argv);

	shell = sh;
	k_work_init_delayable(&work, rng_work);
	shell_set_bypass(sh, rng_bypass);
	k_work_reschedule(&work, K_NO_WAIT);

	return 0;
}

SHELL_STATIC_SUBCMD_SET_CREATE(rng_commands,
	SHELL_CMD(test, NULL, "Run RNG test", cmd_rng_test),
	SHELL_SUBCMD_SET_END
);
SHELL_CMD_REGISTER(rng, &rng_commands, "RNG (Random Number Generator) commands", NULL);

#endif
#endif
```

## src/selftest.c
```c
#include <zephyr/kernel.h>
#include <zephyr/logging/log.h>
#include <zephyr/sys/byteorder.h>

#include <twpm/tpm.h>
#include <twpm/test.h>

#include <stdio.h>

#define SHA256_DIGEST_SIZE 32

#define TPM_TAG_RSP_COMMAND 0x00c4
#define TPM_ST_NO_SESSIONS 0x8001

LOG_MODULE_REGISTER(test);

typedef struct {
	uint16_t tag;
	uint32_t size;
	uint32_t command;
} tpm_command_header;

static uint8_t cmd_tpm_startup[] = {0x80, 0x01, 0x00, 0x00, 0x00, 0x0c, 0x00, 0x00, 0x01, 0x44, 0x00, 0x00};
// static uint8_t cmd_tpm_cap_get_algos[] = {8001000000160000017a00000000000000010000007f}

// TPM response on error:
// u16 - TPM_TAG_RSP_COMMAND or TPM_ST_NO_SESSIONS
// u32 - response size, always 10
// u32 - response code, one of TPM2_RC_*
static uint8_t* execute_command(uint8_t *request, size_t size, bool dump, uint32_t *out_resp_size) {
	static uint8_t resp_buffer[512];
	uint8_t *resp = resp_buffer;
	uint32_t resp_size = sizeof resp_buffer;
	twpm_run_command(size, request, &resp_size, &resp);
	if (out_resp_size) {
		*out_resp_size = resp_size;
	}

	if (dump) {
		LOG_INF("TPM command result: %s", tpmdbg_decode_rc(&resp[6]));
	}

	return resp;
}

static void tpm_hash(uint8_t *buffer, uint8_t size) {
	uint16_t tag = sys_cpu_to_be16(TPM_ST_NO_SESSIONS);
	uint32_t total_size_cpu = size + 12 + 6;
	uint32_t total_size = sys_cpu_to_be32(total_size_cpu);
	uint32_t command = sys_cpu_to_be32(0x0000017d); /* TPM2_CC_Hash */

	uint8_t *request = k_malloc(total_size_cpu);
	memcpy(&request[0], &tag, sizeof tag);
	memcpy(&request[2], &total_size, sizeof total_size);
	memcpy(&request[6], &command, sizeof command);

	*(uint16_t*)&request[10] = sys_cpu_to_be16(size);
	memcpy(&request[12], buffer, size);
	request[12 + size + 0] = 0x00;
	request[12 + size + 1] = 0x0b; /* sha256 */
	request[12 + size + 2] = 0x40;
	request[12 + size + 3] = 0x00;
	request[12 + size + 4] = 0x00;
	request[12 + size + 5] = 0x01;

	k_free(request);
	uint32_t resp_size;
	uint8_t *resp = execute_command(request, total_size_cpu, false, &resp_size);
	if (resp_size < 10) {
		LOG_ERR("TPM response too short");
		return;
	}

	if (sys_get_be32(&resp[6]) == 0) {
		uint32_t real_resp_size = sys_get_be32(&resp[2]);
		if (real_resp_size - 12 < SHA256_DIGEST_SIZE) {
			LOG_ERR("TPM response too short");
			return;
		}
		uint16_t hash_size = sys_get_be16(&resp[10]);

		if (hash_size != SHA256_DIGEST_SIZE) {
			LOG_ERR("HASH: invalid response size %d", real_resp_size);
			LOG_HEXDUMP_ERR(resp, resp_size, "Response:");
		} else {
			char buf[SHA256_DIGEST_SIZE * 2 + 1];
			for (int i = 0; i < SHA256_DIGEST_SIZE; i++) {
				uint8_t b = resp[12 + i];
				snprintf(&buf[i * 2], 3, "%02x", b);
			}
			buf[sizeof buf - 1] = 0;
			LOG_INF("HASH: %s", buf);
		}
	} else {
		LOG_ERR("HASH failed: %s", tpmdbg_decode_rc(resp));
	}
}

void twpm_selftest() {
	execute_command(cmd_tpm_startup, sizeof cmd_tpm_startup, true, NULL);
	tpm_hash("test12345678901234567890987654321\n", 34);
}
```
